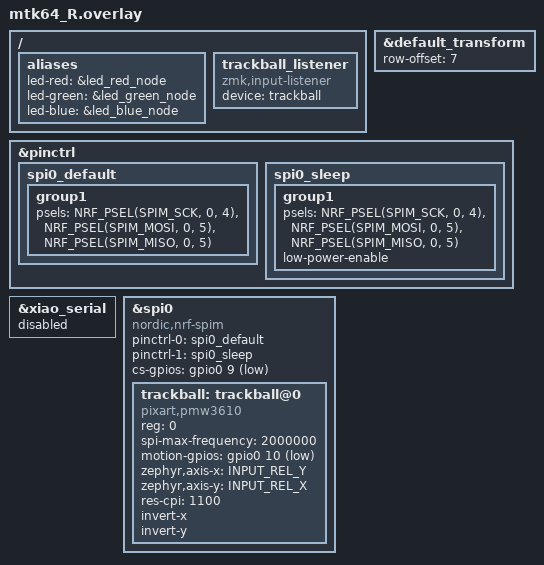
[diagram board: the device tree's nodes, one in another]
#include "mtk64.dtsi"

&default_transform {
    row-offset = <7>;
};

/*
&kscan0 {
    gpios
        = <&xiao_d 1 GPIO_ACTIVE_HIGH> 
        , <&xiao_d 2 GPIO_ACTIVE_HIGH> 
        , <&xiao_d 3 GPIO_ACTIVE_HIGH> 
        , <&xiao_d 6 GPIO_ACTIVE_HIGH>
        , <&xiao_d 7 GPIO_ACTIVE_HIGH> 
        , <&xiao_d 8 GPIO_ACTIVE_HIGH> 
        , <&xiao_d 9 GPIO_ACTIVE_HIGH> 	
    ;
};
*/

/ {
    aliases {
        led-red = &led_red_node;
        led-green = &led_green_node;
        led-blue = &led_blue_node;
    };
    trackball_listener {
        compatible = "zmk,input-listener";
        device = <&trackball>;
    };
};

&pinctrl {
    spi0_default: spi0_default {
        group1 {
            psels = <NRF_PSEL(SPIM_SCK, 0, 4)>,
                <NRF_PSEL(SPIM_MOSI, 0, 5)>,
                <NRF_PSEL(SPIM_MISO, 0, 5)>;
        };
    };

    spi0_sleep: spi0_sleep {
        group1 {
            psels = <NRF_PSEL(SPIM_SCK, 0, 4)>,
                <NRF_PSEL(SPIM_MOSI, 0, 5)>,
                <NRF_PSEL(SPIM_MISO, 0, 5)>;
            low-power-enable;
        };
    };
};

&xiao_serial { status = "disabled"; };

&spi0 {
    status = "okay";
    compatible = "nordic,nrf-spim";
    pinctrl-0 = <&spi0_default>;
    pinctrl-1 = <&spi0_sleep>;
    pinctrl-names = "default", "sleep";
    cs-gpios = <&gpio0 9 GPIO_ACTIVE_LOW>;

    trackball: trackball@0 {
        status = "okay";
        compatible = "pixart,pmw3610";
        reg = <0>;
        spi-max-frequency = <2000000>;
        motion-gpios = <&gpio0 10 (GPIO_ACTIVE_LOW | GPIO_PULL_UP)>; 
        zephyr,axis-x = <INPUT_REL_X>;
        zephyr,axis-y = <INPUT_REL_Y>;
 compatible = "pixart,pmw3610";
    /* 既存の reg, spi-max-frequency, motion-gpios は残す */

    /* 解像度の設定 (CPI) */
    res-cpi = <1100>;

    /* 軸の反転 (CONFIG_PMW3610_INVERT_X=y の代わり) */
   invert-x;

    /* 90度回転 (ORIENTATION_90=y の代わり) */
    /* 90度回転の場合、通常は軸の割り当てを入れ替えます */
    zephyr,axis-x = <INPUT_REL_Y>;
    zephyr,axis-y = <INPUT_REL_X>;
    invert-y; /* 必要に応じて調整 */
    };
};


